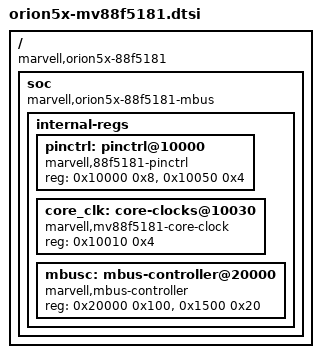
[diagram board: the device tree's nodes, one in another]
/*
 * Copyright (C) 2016 Jamie Lentin <jm@lentin.co.uk>
 *
 * This file is licensed under the terms of the GNU General Public
 * License version 2. This program is licensed "as is" without any
 * warranty of any kind, whether express or implied.
 */

#include "orion5x.dtsi"

/ {
	compatible = "marvell,orion5x-88f5181", "marvell,orion5x";

	soc {
		compatible = "marvell,orion5x-88f5181-mbus", "simple-bus";

		internal-regs {
			pinctrl: pinctrl@10000 {
				compatible = "marvell,88f5181-pinctrl";
				reg = <0x10000 0x8>, <0x10050 0x4>;
				/*
				TODO: From board/mv88fxx81/Soc/ctrlEnv/MV_88FXX81/mvCtrlEnvSpec.h
				#define MPP_CONTROL_REG0                                0x10000
				#define MPP_CONTROL_REG1                                0x10004
				#define MPP_CONTROL_REG2                                0x10050
				#define DEV_MULTI_CONTROL                               0x10008
				*/
			};

			core_clk: core-clocks@10030 {
				compatible = "marvell,mv88f5181-core-clock";
				reg = <0x10010 0x4>;
				#clock-cells = <1>;
			};

			mbusc: mbus-controller@20000 {
				compatible = "marvell,mbus-controller";
				reg = <0x20000 0x100>, <0x1500 0x20>;
			};
		};
	};
};
